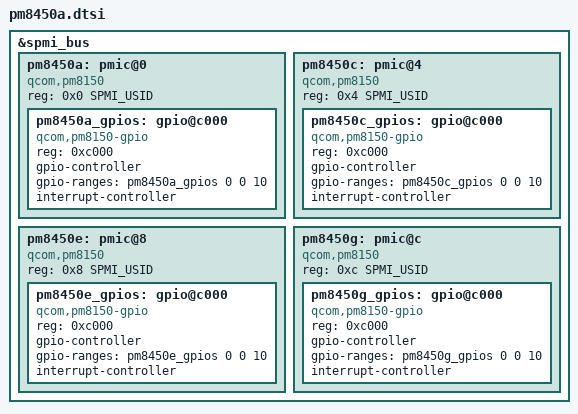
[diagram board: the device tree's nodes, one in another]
// SPDX-License-Identifier: BSD-3-Clause
/*
 * Copyright (c) 2021, The Linux Foundation. All rights reserved.
 * Copyright (c) 2022, Linaro Limited
 */

#include <dt-bindings/spmi/spmi.h>

&spmi_bus {
	pm8450a: pmic@0 {
		compatible = "qcom,pm8150", "qcom,spmi-pmic";
		reg = <0x0 SPMI_USID>;
		#address-cells = <1>;
		#size-cells = <0>;

		pm8450a_gpios: gpio@c000 {
			compatible = "qcom,pm8150-gpio", "qcom,spmi-gpio";
			reg = <0xc000>;
			gpio-controller;
			gpio-ranges = <&pm8450a_gpios 0 0 10>;
			#gpio-cells = <2>;
			interrupt-controller;
			#interrupt-cells = <2>;
		};
	};

	pm8450c: pmic@4 {
		compatible = "qcom,pm8150", "qcom,spmi-pmic";
		reg = <0x4 SPMI_USID>;
		#address-cells = <1>;
		#size-cells = <0>;

		pm8450c_gpios: gpio@c000 {
			compatible = "qcom,pm8150-gpio", "qcom,spmi-gpio";
			reg = <0xc000>;
			gpio-controller;
			gpio-ranges = <&pm8450c_gpios 0 0 10>;
			#gpio-cells = <2>;
			interrupt-controller;
			#interrupt-cells = <2>;
		};
	};

	pm8450e: pmic@8 {
		compatible = "qcom,pm8150", "qcom,spmi-pmic";
		reg = <0x8 SPMI_USID>;
		#address-cells = <1>;
		#size-cells = <0>;

		pm8450e_gpios: gpio@c000 {
			compatible = "qcom,pm8150-gpio", "qcom,spmi-gpio";
			reg = <0xc000>;
			gpio-controller;
			gpio-ranges = <&pm8450e_gpios 0 0 10>;
			#gpio-cells = <2>;
			interrupt-controller;
			#interrupt-cells = <2>;
		};
	};

	pm8450g: pmic@c {
		compatible = "qcom,pm8150", "qcom,spmi-pmic";
		reg = <0xc SPMI_USID>;
		#address-cells = <1>;
		#size-cells = <0>;

		pm8450g_gpios: gpio@c000 {
			compatible = "qcom,pm8150-gpio", "qcom,spmi-gpio";
			reg = <0xc000>;
			gpio-controller;
			gpio-ranges = <&pm8450g_gpios 0 0 10>;
			#gpio-cells = <2>;
			interrupt-controller;
			#interrupt-cells = <2>;
		};
	};
};
